# RL7005_IP_SVD register map
Vendor: Realtek
Registers are 32-bit, read-write, reset 0x0 unless marked. A register's access mark holds for its fields unless they carry their own. Offsets are from the block's base; [hi:lo] are bit positions; lines under a group give offsets from that group; {n}, {i} and the like mark numbered series.

## SYSTEM_MEM_CTRL
Base 0x4080A600
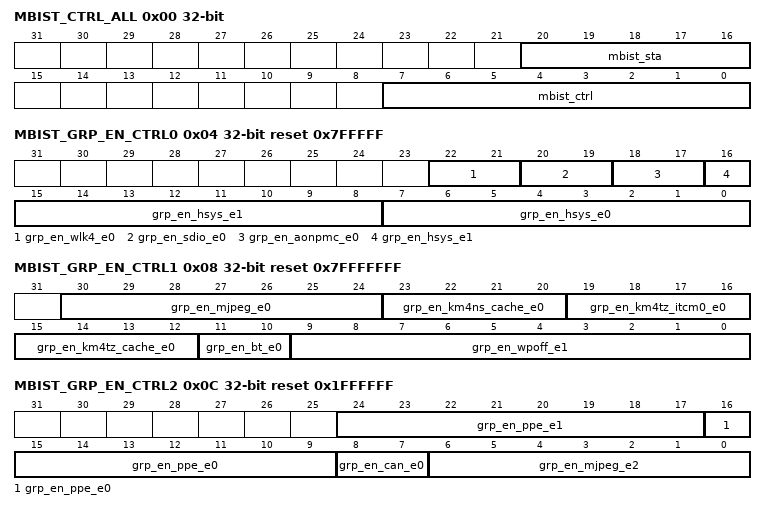
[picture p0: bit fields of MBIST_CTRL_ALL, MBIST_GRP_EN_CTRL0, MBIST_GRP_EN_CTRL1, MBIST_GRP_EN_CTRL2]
0x00 MBIST_CTRL_ALL access per field — MEMx MBIST control and status register
  [20:16] mbist_sta ro — Total mbist status [16] MBIST DRF_START_PAUSE [17] MBIST NRML_DONE_ALL [18] MBIST NRML_FAIL_ALL [19] MBIST DRF_DONE_ALL [20] MBIST DRF_FAIL_ALL
  [7:0] mbist_ctrl rw — Total mbist control [0] MBIST_CLK_EN_ALL BIS_CLK enable of all system memory groups. [1] MBIST_RSTB_ALL Reset controll mbist circuit of all system memory groups. [3:2]MBIST_MSEL_ALL mbist method selection of all memory groups: 2'b01: enable normal mode mbist 2'b10: enable DRF mode mbist 2'b11: enable normal&DRF mode mbist [4]MBIST_RESUME [5]MBIST_RESUME_PS [6]MBIST_DYN_READ_EN If MBIST_MSEL_ALL[1]=1 & MBIST_DYN_READ_EN=1, run VDDR mode mbist. 7]MBIST_PHYCLK_STOP
0x04 MBIST_GRP_EN_CTRL0 reset 0x7FFFFF — Used to on-off mbist of memory block in a group.
  [22:21] grp_en_wlk4_e0, [20:19] grp_en_sdio_e0, [18:17] grp_en_aonpmc_e0, [16:8] grp_en_hsys_e1, [7:0] grp_en_hsys_e0
0x08 MBIST_GRP_EN_CTRL1 reset 0x7FFFFFFF — Used to on-off mbist of memory block in a group.
  [30:24] grp_en_mjpeg_e0, [23:20] grp_en_km4ns_cache_e0, [19:16] grp_en_km4tz_itcm0_e0, [15:12] grp_en_km4tz_cache_e0, [11:10] grp_en_bt_e0, [9:0] grp_en_wpoff_e1
0x0C MBIST_GRP_EN_CTRL2 reset 0x1FFFFFF — Used to on-off mbist of memory block in a group.
  [24:17] grp_en_ppe_e1, [16:9] grp_en_ppe_e0, [8:7] grp_en_can_e0, [6:0] grp_en_mjpeg_e2
0x10 MBIST_GRP_EN_BT_VIR_E00 reset 0xFFFFF
  [19:0] bt_vir_e0_bist_en_19_0
0x14 MBIST_DONE_STA0 ro
  [31:0] mbist_done_31_0
0x18 MBIST_START_PULSE0 ro
  [31:0] mbist_start_pause_31_0
{0x1C+4i} MBIST_NORM_FAIL{i} ro (i=0..2)
  [31:0] mbist_norm_fail_{32i+31}_{32i}
0x28 MBIST_NORM_FAIL3 ro
  [3:0] mbist_norm_fail_99_96
{0x2C+4i} MBIST_DRF_FAIL{i} ro (i=0..2)
  [31:0] mbist_drf_fail_{32i+31}_{32i}
0x38 MBIST_DRF_FAIL3 ro
  [3:0] mbist_drf_fail_99_96
0x3C BT_VIR_E0_BIST_DONE0 ro
  [19:0] bt_vir_e0_mbist_done_19_0
0x40 BT_VIR_E0_BIST_FAIL0 ro
  [19:0] bt_vir_e0_mbist_fail_19_0
0x44 BT_VIR_E0_BIST_DRF_PAUSE0 ro
  [19:0] bt_vir_e0_mbist_drf_pause_19_0
0x48 BT_VIR_E0_BIST_RPT ro
  [31:0] bt_vir_e0_bist_rpt_dout
0x4C BT_VIR_E0_RPT_SEL
  [3:0] bt_vir_e0_rpt_sel — Select which rom's misr_dataout or bist_status of each memory can be read from bt_vir_e0_bist_rpt
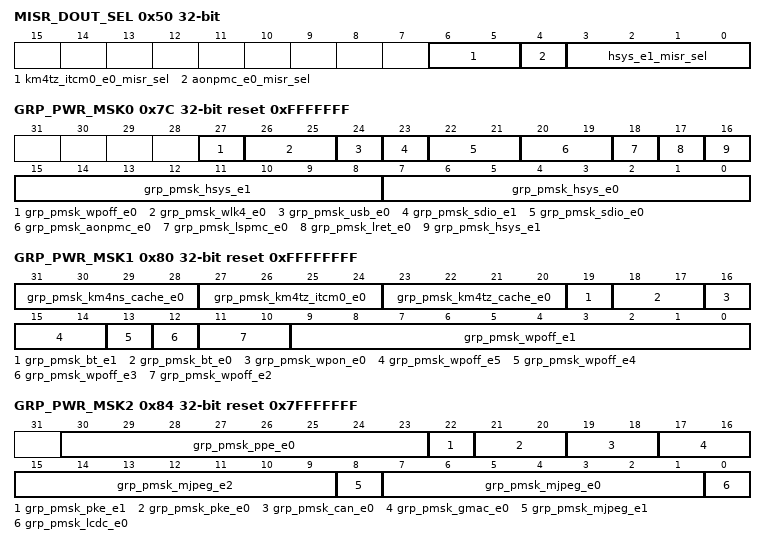
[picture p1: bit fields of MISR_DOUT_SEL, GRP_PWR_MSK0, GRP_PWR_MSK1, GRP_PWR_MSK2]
0x50 MISR_DOUT_SEL
  [6:5] km4tz_itcm0_e0_misr_sel, [4] aonpmc_e0_misr_sel, [3:0] hsys_e1_misr_sel
0x54 HSYS_E1_ROM_MISR0 ro
  [31:0] hsys_e1_misr_dout_31_0
0x58 HSYS_E1_ROM_MISR1 ro
  [31:0] hsys_e1_misr_dout_63_32
0x5C LSPMC_E0_ROM_MISR1 ro
  [31:0] lspmc_e0_misr_dout_31_0
0x60 LSPMC_E0_ROM_MISR2 ro
  [3:0] lspmc_e0_misr_dout_35_32
0x64 AONPMC_E0_ROM_MISR2 ro
  [31:0] aonpmc_e0_misr_dout_31_0
0x68 AONPMC_E0_ROM_MISR3 ro
  [3:0] aonpmc_e0_misr_dout_35_32
0x6C KM4TZ_ITCM0_E0_ROM_MISR3 ro
  [31:0] km4tz_itcm0_e0_misr_dout_31_0
0x70 KM4TZ_ITCM0_E0_ROM_MISR4 ro
  [31:0] km4tz_itcm0_e0_misr_dout_63_32
0x74 PKE_E1_ROM_MISR4 ro
  [31:0] pke_e1_misr_dout_31_0
0x78 PKE_E1_ROM_MISR5 ro
  [31:0] pke_e1_misr_dout_63_32
0x7C GRP_PWR_MSK0 reset 0xFFFFFFF
  [27] grp_pmsk_wpoff_e0, [26:25] grp_pmsk_wlk4_e0, [24] grp_pmsk_usb_e0, [23] grp_pmsk_sdio_e1, [22:21] grp_pmsk_sdio_e0, [20:19] grp_pmsk_aonpmc_e0, [18] grp_pmsk_lspmc_e0, [17] grp_pmsk_lret_e0, [16:8] grp_pmsk_hsys_e1, [7:0] grp_pmsk_hsys_e0
0x80 GRP_PWR_MSK1 reset 0xFFFFFFFF
  [31:28] grp_pmsk_km4ns_cache_e0, [27:24] grp_pmsk_km4tz_itcm0_e0, [23:20] grp_pmsk_km4tz_cache_e0, [19] grp_pmsk_bt_e1, [18:17] grp_pmsk_bt_e0, [16] grp_pmsk_wpon_e0, [15:14] grp_pmsk_wpoff_e5, [13] grp_pmsk_wpoff_e4, [12] grp_pmsk_wpoff_e3, [11:10] grp_pmsk_wpoff_e2, [9:0] grp_pmsk_wpoff_e1
0x84 GRP_PWR_MSK2 reset 0x7FFFFFFF
  [30:23] grp_pmsk_ppe_e0, [22] grp_pmsk_pke_e1, [21:20] grp_pmsk_pke_e0, [19:18] grp_pmsk_can_e0, [17:16] grp_pmsk_gmac_e0, [15:9] grp_pmsk_mjpeg_e2, [8] grp_pmsk_mjpeg_e1, [7:1] grp_pmsk_mjpeg_e0, [0] grp_pmsk_lcdc_e0
0x88 GRP_PWR_MSK3 reset 0xFF
  [7:0] grp_pmsk_ppe_e1
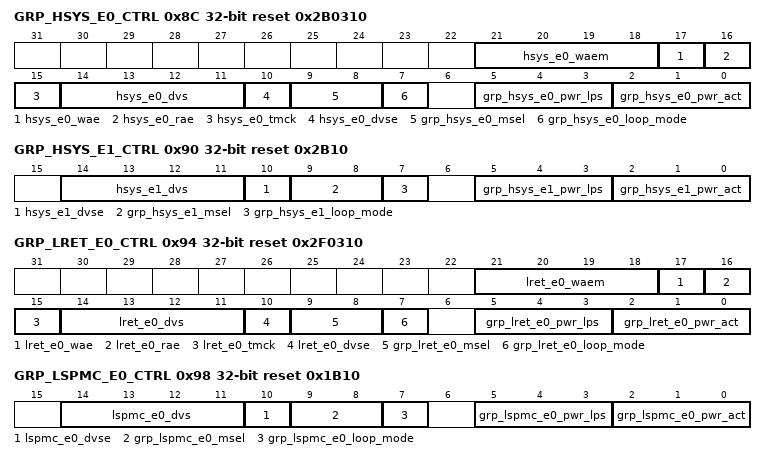
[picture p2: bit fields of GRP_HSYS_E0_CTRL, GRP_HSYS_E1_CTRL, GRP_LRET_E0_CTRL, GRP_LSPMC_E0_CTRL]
0x8C GRP_HSYS_E0_CTRL reset 0x2B0310
  [21:18] hsys_e0_waem — WAEM
  [17] hsys_e0_wae — WAE
  [16] hsys_e0_rae — RAE
  [15] hsys_e0_tmck — TMCK
  [14:11] hsys_e0_dvs — DVS
  [10] hsys_e0_dvse — DVSE
  [9:8] grp_hsys_e0_msel — *01 - This memory group can do normal mbist; *10 - This memory group can do DRF mbist; *11 - This memory group can do normal & DRF mbist
  [7] grp_hsys_e0_loop_mode — *0 - Assist loop mode; *1 - Don't assist loop mode
  [5:3] grp_hsys_e0_pwr_lps — Reserved for grp_@_pwr_lps for memory groups power controlled by SYSPMC. Setted before chip goes to SLEEP.Used to controll power mode of this memory group when chip is in SLEEP. For FTC_ULP mem, pwr_lps[2:0] map to {SLP,RET,NAP}; For SNPS mem, pwr_lps[2:0] map to {SD,DS,LS}. *000 - active *001 - light sleep *010 - deep sleep *100 - shut down
  [2:0] grp_hsys_e0_pwr_act — Used to controll power mode of this memory group when chip is ACTIVE. For FTC_ULP mem, pwr_act[2:0] map to {SLP,RET,NAP}; For SNPS mem, pwr_act[2:0] map to {SD,DS,LS}. *000 - active *001 - light sleep *010 - deep sleep *100 - shut down
0x90 GRP_HSYS_E1_CTRL reset 0x2B10
  [14:11] hsys_e1_dvs — DVS
  [10] hsys_e1_dvse — DVSE
  [9:8] grp_hsys_e1_msel — *01 - This memory group can do normal mbist; *10 - This memory group can do DRF mbist; *11 - This memory group can do normal & DRF mbist
  [7] grp_hsys_e1_loop_mode — *0 - Assist loop mode; *1 - Don't assist loop mode
  [5:3] grp_hsys_e1_pwr_lps — Reserved for grp_@_pwr_lps for memory groups power controlled by SYSPMC. Setted before chip goes to SLEEP.Used to controll power mode of this memory group when chip is in SLEEP. For FTC_ULP mem, pwr_lps[2:0] map to {SLP,RET,NAP}; For SNPS mem, pwr_lps[2:0] map to {SD,DS,LS}. *000 - active *001 - light sleep *010 - deep sleep *100 - shut down
  [2:0] grp_hsys_e1_pwr_act — Used to controll power mode of this memory group when chip is ACTIVE. For FTC_ULP mem, pwr_act[2:0] map to {SLP,RET,NAP}; For SNPS mem, pwr_act[2:0] map to {SD,DS,LS}. *000 - active *001 - light sleep *010 - deep sleep *100 - shut down
0x94 GRP_LRET_E0_CTRL reset 0x2F0310
  [21:18] lret_e0_waem — WAEM
  [17] lret_e0_wae — WAE
  [16] lret_e0_rae — RAE
  [15] lret_e0_tmck — TMCK
  [14:11] lret_e0_dvs — DVS
  [10] lret_e0_dvse — DVSE
  [9:8] grp_lret_e0_msel — *01 - This memory group can do normal mbist; *10 - This memory group can do DRF mbist; *11 - This memory group can do normal & DRF mbist
  [7] grp_lret_e0_loop_mode — *0 - Assist loop mode; *1 - Don't assist loop mode
  [5:3] grp_lret_e0_pwr_lps — Reserved for grp_@_pwr_lps for memory groups power controlled by SYSPMC. Setted before chip goes to SLEEP.Used to controll power mode of this memory group when chip is in SLEEP. For FTC_ULP mem, pwr_lps[2:0] map to {SLP,RET,NAP}; For SNPS mem, pwr_lps[2:0] map to {SD,DS,LS}. *000 - active *001 - light sleep *010 - deep sleep *100 - shut down
  [2:0] grp_lret_e0_pwr_act — Used to controll power mode of this memory group when chip is ACTIVE. For FTC_ULP mem, pwr_act[2:0] map to {SLP,RET,NAP}; For SNPS mem, pwr_act[2:0] map to {SD,DS,LS}. *000 - active *001 - light sleep *010 - deep sleep *100 - shut down
0x98 GRP_LSPMC_E0_CTRL reset 0x1B10
  [14:11] lspmc_e0_dvs — DVS
  [10] lspmc_e0_dvse — DVSE
  [9:8] grp_lspmc_e0_msel — *01 - This memory group can do normal mbist; *10 - This memory group can do DRF mbist; *11 - This memory group can do normal & DRF mbist
  [7] grp_lspmc_e0_loop_mode — *0 - Assist loop mode; *1 - Don't assist loop mode
  [5:3] grp_lspmc_e0_pwr_lps — Reserved for grp_@_pwr_lps for memory groups power controlled by SYSPMC. Setted before chip goes to SLEEP.Used to controll power mode of this memory group when chip is in SLEEP. For FTC_ULP mem, pwr_lps[2:0] map to {SLP,RET,NAP}; For SNPS mem, pwr_lps[2:0] map to {SD,DS,LS}. *000 - active *001 - light sleep *010 - deep sleep *100 - shut down
  [2:0] grp_lspmc_e0_pwr_act — Used to controll power mode of this memory group when chip is ACTIVE. For FTC_ULP mem, pwr_act[2:0] map to {SLP,RET,NAP}; For SNPS mem, pwr_act[2:0] map to {SD,DS,LS}. *000 - active *001 - light sleep *010 - deep sleep *100 - shut down
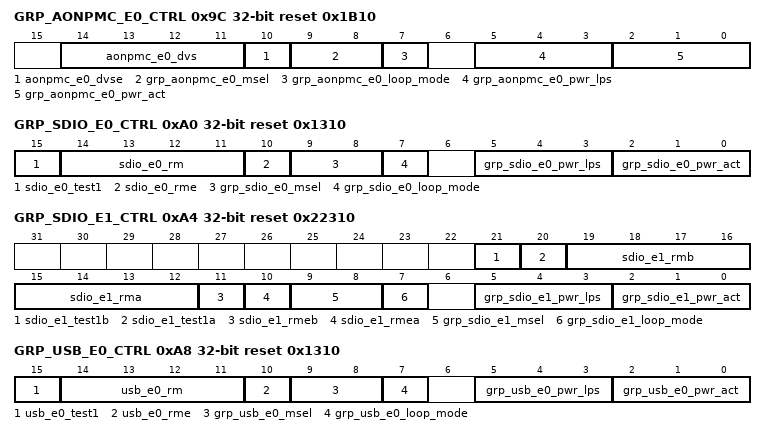
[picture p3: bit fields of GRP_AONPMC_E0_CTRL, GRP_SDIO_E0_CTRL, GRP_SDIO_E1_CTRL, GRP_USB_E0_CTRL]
0x9C GRP_AONPMC_E0_CTRL reset 0x1B10
  [14:11] aonpmc_e0_dvs — DVS
  [10] aonpmc_e0_dvse — DVSE
  [9:8] grp_aonpmc_e0_msel — *01 - This memory group can do normal mbist; *10 - This memory group can do DRF mbist; *11 - This memory group can do normal & DRF mbist
  [7] grp_aonpmc_e0_loop_mode — *0 - Assist loop mode; *1 - Don't assist loop mode
  [5:3] grp_aonpmc_e0_pwr_lps — Reserved for grp_@_pwr_lps for memory groups power controlled by SYSPMC. Setted before chip goes to SLEEP.Used to controll power mode of this memory group when chip is in SLEEP. For FTC_ULP mem, pwr_lps[2:0] map to {SLP,RET,NAP}; For SNPS mem, pwr_lps[2:0] map to {SD,DS,LS}. *000 - active *001 - light sleep *010 - deep sleep *100 - shut down
  [2:0] grp_aonpmc_e0_pwr_act — Used to controll power mode of this memory group when chip is ACTIVE. For FTC_ULP mem, pwr_act[2:0] map to {SLP,RET,NAP}; For SNPS mem, pwr_act[2:0] map to {SD,DS,LS}. *000 - active *001 - light sleep *010 - deep sleep *100 - shut down
0xA0 GRP_SDIO_E0_CTRL reset 0x1310
  [15] sdio_e0_test1 — TEST1
  [14:11] sdio_e0_rm — RM
  [10] sdio_e0_rme — RME
  [9:8] grp_sdio_e0_msel — *01 - This memory group can do normal mbist; *10 - This memory group can do DRF mbist; *11 - This memory group can do normal & DRF mbist
  [7] grp_sdio_e0_loop_mode — *0 - Assist loop mode; *1 - Don't assist loop mode
  [5:3] grp_sdio_e0_pwr_lps — Reserved for grp_@_pwr_lps for memory groups power controlled by SYSPMC. Setted before chip goes to SLEEP.Used to controll power mode of this memory group when chip is in SLEEP. For FTC_ULP mem, pwr_lps[2:0] map to {SLP,RET,NAP}; For SNPS mem, pwr_lps[2:0] map to {SD,DS,LS}. *000 - active *001 - light sleep *010 - deep sleep *100 - shut down
  [2:0] grp_sdio_e0_pwr_act — Used to controll power mode of this memory group when chip is ACTIVE. For FTC_ULP mem, pwr_act[2:0] map to {SLP,RET,NAP}; For SNPS mem, pwr_act[2:0] map to {SD,DS,LS}. *000 - active *001 - light sleep *010 - deep sleep *100 - shut down
0xA4 GRP_SDIO_E1_CTRL reset 0x22310
  [21] sdio_e1_test1b — TEST1B
  [20] sdio_e1_test1a — TEST1A
  [19:16] sdio_e1_rmb — RMB
  [15:12] sdio_e1_rma — RMA
  [11] sdio_e1_rmeb — RMEB
  [10] sdio_e1_rmea — RMEA
  [9:8] grp_sdio_e1_msel — *01 - This memory group can do normal mbist; *10 - This memory group can do DRF mbist; *11 - This memory group can do normal & DRF mbist
  [7] grp_sdio_e1_loop_mode — *0 - Assist loop mode; *1 - Don't assist loop mode
  [5:3] grp_sdio_e1_pwr_lps — Reserved for grp_@_pwr_lps for memory groups power controlled by SYSPMC. Setted before chip goes to SLEEP.Used to controll power mode of this memory group when chip is in SLEEP. For FTC_ULP mem, pwr_lps[2:0] map to {SLP,RET,NAP}; For SNPS mem, pwr_lps[2:0] map to {SD,DS,LS}. *000 - active *001 - light sleep *010 - deep sleep *100 - shut down
  [2:0] grp_sdio_e1_pwr_act — Used to controll power mode of this memory group when chip is ACTIVE. For FTC_ULP mem, pwr_act[2:0] map to {SLP,RET,NAP}; For SNPS mem, pwr_act[2:0] map to {SD,DS,LS}. *000 - active *001 - light sleep *010 - deep sleep *100 - shut down
0xA8 GRP_USB_E0_CTRL reset 0x1310
  [15] usb_e0_test1 — TEST1
  [14:11] usb_e0_rm — RM
  [10] usb_e0_rme — RME
  [9:8] grp_usb_e0_msel — *01 - This memory group can do normal mbist; *10 - This memory group can do DRF mbist; *11 - This memory group can do normal & DRF mbist
  [7] grp_usb_e0_loop_mode — *0 - Assist loop mode; *1 - Don't assist loop mode
  [5:3] grp_usb_e0_pwr_lps — Reserved for grp_@_pwr_lps for memory groups power controlled by SYSPMC. Setted before chip goes to SLEEP.Used to controll power mode of this memory group when chip is in SLEEP. For FTC_ULP mem, pwr_lps[2:0] map to {SLP,RET,NAP}; For SNPS mem, pwr_lps[2:0] map to {SD,DS,LS}. *000 - active *001 - light sleep *010 - deep sleep *100 - shut down
  [2:0] grp_usb_e0_pwr_act — Used to controll power mode of this memory group when chip is ACTIVE. For FTC_ULP mem, pwr_act[2:0] map to {SLP,RET,NAP}; For SNPS mem, pwr_act[2:0] map to {SD,DS,LS}. *000 - active *001 - light sleep *010 - deep sleep *100 - shut down
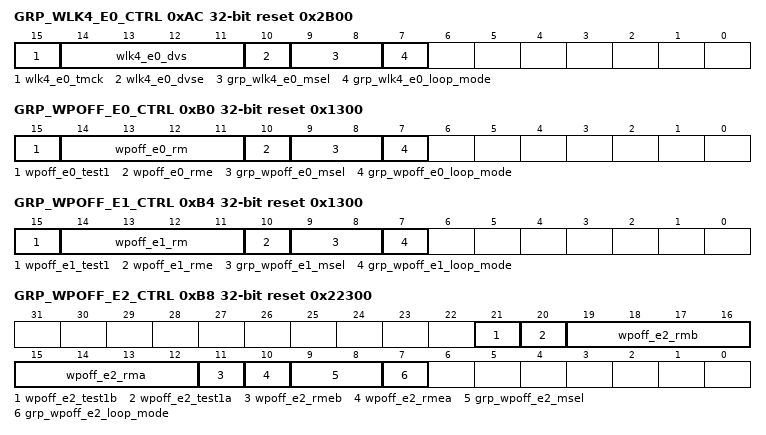
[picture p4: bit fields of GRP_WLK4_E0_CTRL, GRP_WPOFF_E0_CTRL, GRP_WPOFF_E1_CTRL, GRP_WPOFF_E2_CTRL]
0xAC GRP_WLK4_E0_CTRL reset 0x2B00
  [15] wlk4_e0_tmck — TMCK
  [14:11] wlk4_e0_dvs — DVS
  [10] wlk4_e0_dvse — DVSE
  [9:8] grp_wlk4_e0_msel — *01 - This memory group can do normal mbist; *10 - This memory group can do DRF mbist; *11 - This memory group can do normal & DRF mbist
  [7] grp_wlk4_e0_loop_mode — *0 - Assist loop mode; *1 - Don't assist loop mode
0xB0 GRP_WPOFF_E0_CTRL reset 0x1300
  [15] wpoff_e0_test1 — TEST1
  [14:11] wpoff_e0_rm — RM
  [10] wpoff_e0_rme — RME
  [9:8] grp_wpoff_e0_msel — *01 - This memory group can do normal mbist; *10 - This memory group can do DRF mbist; *11 - This memory group can do normal & DRF mbist
  [7] grp_wpoff_e0_loop_mode — *0 - Assist loop mode; *1 - Don't assist loop mode
0xB4 GRP_WPOFF_E1_CTRL reset 0x1300
  [15] wpoff_e1_test1 — TEST1
  [14:11] wpoff_e1_rm — RM
  [10] wpoff_e1_rme — RME
  [9:8] grp_wpoff_e1_msel — *01 - This memory group can do normal mbist; *10 - This memory group can do DRF mbist; *11 - This memory group can do normal & DRF mbist
  [7] grp_wpoff_e1_loop_mode — *0 - Assist loop mode; *1 - Don't assist loop mode
0xB8 GRP_WPOFF_E2_CTRL reset 0x22300
  [21] wpoff_e2_test1b — TEST1B
  [20] wpoff_e2_test1a — TEST1A
  [19:16] wpoff_e2_rmb — RMB
  [15:12] wpoff_e2_rma — RMA
  [11] wpoff_e2_rmeb — RMEB
  [10] wpoff_e2_rmea — RMEA
  [9:8] grp_wpoff_e2_msel — *01 - This memory group can do normal mbist; *10 - This memory group can do DRF mbist; *11 - This memory group can do normal & DRF mbist
  [7] grp_wpoff_e2_loop_mode — *0 - Assist loop mode; *1 - Don't assist loop mode
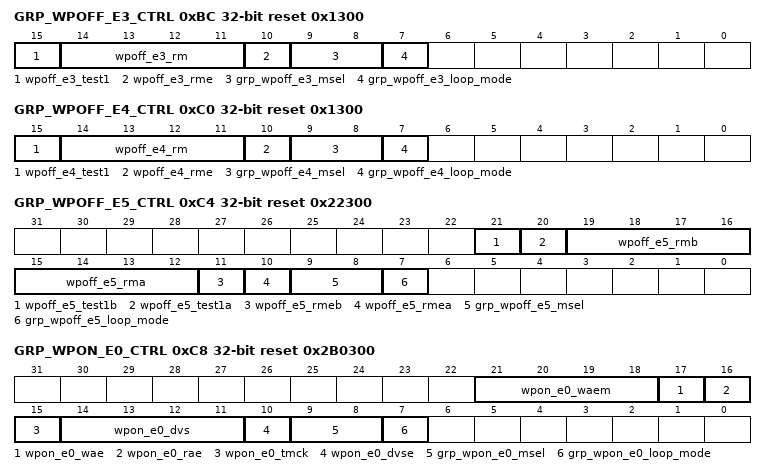
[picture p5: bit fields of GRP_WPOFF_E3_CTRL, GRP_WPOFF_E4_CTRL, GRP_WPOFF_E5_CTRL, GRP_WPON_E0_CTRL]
0xBC GRP_WPOFF_E3_CTRL reset 0x1300
  [15] wpoff_e3_test1 — TEST1
  [14:11] wpoff_e3_rm — RM
  [10] wpoff_e3_rme — RME
  [9:8] grp_wpoff_e3_msel — *01 - This memory group can do normal mbist; *10 - This memory group can do DRF mbist; *11 - This memory group can do normal & DRF mbist
  [7] grp_wpoff_e3_loop_mode — *0 - Assist loop mode; *1 - Don't assist loop mode
0xC0 GRP_WPOFF_E4_CTRL reset 0x1300
  [15] wpoff_e4_test1 — TEST1
  [14:11] wpoff_e4_rm — RM
  [10] wpoff_e4_rme — RME
  [9:8] grp_wpoff_e4_msel — *01 - This memory group can do normal mbist; *10 - This memory group can do DRF mbist; *11 - This memory group can do normal & DRF mbist
  [7] grp_wpoff_e4_loop_mode — *0 - Assist loop mode; *1 - Don't assist loop mode
0xC4 GRP_WPOFF_E5_CTRL reset 0x22300
  [21] wpoff_e5_test1b — TEST1B
  [20] wpoff_e5_test1a — TEST1A
  [19:16] wpoff_e5_rmb — RMB
  [15:12] wpoff_e5_rma — RMA
  [11] wpoff_e5_rmeb — RMEB
  [10] wpoff_e5_rmea — RMEA
  [9:8] grp_wpoff_e5_msel — *01 - This memory group can do normal mbist; *10 - This memory group can do DRF mbist; *11 - This memory group can do normal & DRF mbist
  [7] grp_wpoff_e5_loop_mode — *0 - Assist loop mode; *1 - Don't assist loop mode
0xC8 GRP_WPON_E0_CTRL reset 0x2B0300
  [21:18] wpon_e0_waem — WAEM
  [17] wpon_e0_wae — WAE
  [16] wpon_e0_rae — RAE
  [15] wpon_e0_tmck — TMCK
  [14:11] wpon_e0_dvs — DVS
  [10] wpon_e0_dvse — DVSE
  [9:8] grp_wpon_e0_msel — *01 - This memory group can do normal mbist; *10 - This memory group can do DRF mbist; *11 - This memory group can do normal & DRF mbist
  [7] grp_wpon_e0_loop_mode — *0 - Assist loop mode; *1 - Don't assist loop mode
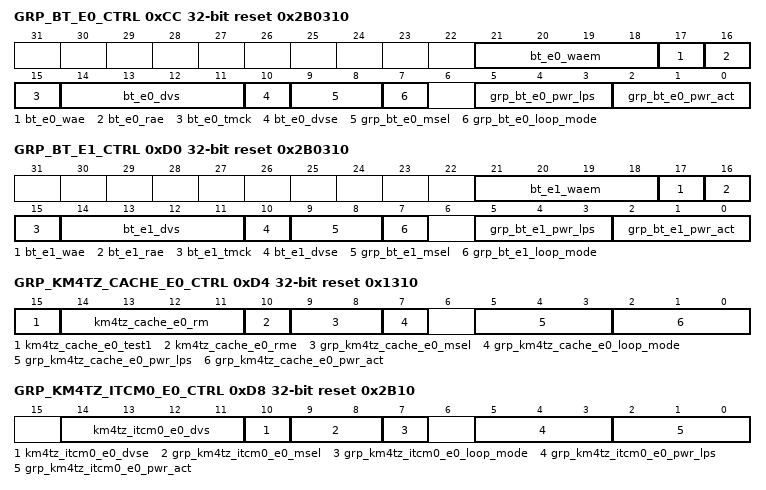
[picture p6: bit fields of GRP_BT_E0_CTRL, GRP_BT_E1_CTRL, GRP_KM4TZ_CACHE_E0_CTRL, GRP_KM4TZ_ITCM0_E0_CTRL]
0xCC GRP_BT_E0_CTRL reset 0x2B0310
  [21:18] bt_e0_waem — WAEM
  [17] bt_e0_wae — WAE
  [16] bt_e0_rae — RAE
  [15] bt_e0_tmck — TMCK
  [14:11] bt_e0_dvs — DVS
  [10] bt_e0_dvse — DVSE
  [9:8] grp_bt_e0_msel — *01 - This memory group can do normal mbist; *10 - This memory group can do DRF mbist; *11 - This memory group can do normal & DRF mbist
  [7] grp_bt_e0_loop_mode — *0 - Assist loop mode; *1 - Don't assist loop mode
  [5:3] grp_bt_e0_pwr_lps — Reserved for grp_@_pwr_lps for memory groups power controlled by SYSPMC. Setted before chip goes to SLEEP.Used to controll power mode of this memory group when chip is in SLEEP. For FTC_ULP mem, pwr_lps[2:0] map to {SLP,RET,NAP}; For SNPS mem, pwr_lps[2:0] map to {SD,DS,LS}. *000 - active *001 - light sleep *010 - deep sleep *100 - shut down
  [2:0] grp_bt_e0_pwr_act — Used to controll power mode of this memory group when chip is ACTIVE. For FTC_ULP mem, pwr_act[2:0] map to {SLP,RET,NAP}; For SNPS mem, pwr_act[2:0] map to {SD,DS,LS}. *000 - active *001 - light sleep *010 - deep sleep *100 - shut down
0xD0 GRP_BT_E1_CTRL reset 0x2B0310
  [21:18] bt_e1_waem — WAEM
  [17] bt_e1_wae — WAE
  [16] bt_e1_rae — RAE
  [15] bt_e1_tmck — TMCK
  [14:11] bt_e1_dvs — DVS
  [10] bt_e1_dvse — DVSE
  [9:8] grp_bt_e1_msel — *01 - This memory group can do normal mbist; *10 - This memory group can do DRF mbist; *11 - This memory group can do normal & DRF mbist
  [7] grp_bt_e1_loop_mode — *0 - Assist loop mode; *1 - Don't assist loop mode
  [5:3] grp_bt_e1_pwr_lps — Reserved for grp_@_pwr_lps for memory groups power controlled by SYSPMC. Setted before chip goes to SLEEP.Used to controll power mode of this memory group when chip is in SLEEP. For FTC_ULP mem, pwr_lps[2:0] map to {SLP,RET,NAP}; For SNPS mem, pwr_lps[2:0] map to {SD,DS,LS}. *000 - active *001 - light sleep *010 - deep sleep *100 - shut down
  [2:0] grp_bt_e1_pwr_act — Used to controll power mode of this memory group when chip is ACTIVE. For FTC_ULP mem, pwr_act[2:0] map to {SLP,RET,NAP}; For SNPS mem, pwr_act[2:0] map to {SD,DS,LS}. *000 - active *001 - light sleep *010 - deep sleep *100 - shut down
0xD4 GRP_KM4TZ_CACHE_E0_CTRL reset 0x1310
  [15] km4tz_cache_e0_test1 — TEST1
  [14:11] km4tz_cache_e0_rm — RM
  [10] km4tz_cache_e0_rme — RME
  [9:8] grp_km4tz_cache_e0_msel — *01 - This memory group can do normal mbist; *10 - This memory group can do DRF mbist; *11 - This memory group can do normal & DRF mbist
  [7] grp_km4tz_cache_e0_loop_mode — *0 - Assist loop mode; *1 - Don't assist loop mode
  [5:3] grp_km4tz_cache_e0_pwr_lps — Reserved for grp_@_pwr_lps for memory groups power controlled by SYSPMC. Setted before chip goes to SLEEP.Used to controll power mode of this memory group when chip is in SLEEP. For FTC_ULP mem, pwr_lps[2:0] map to {SLP,RET,NAP}; For SNPS mem, pwr_lps[2:0] map to {SD,DS,LS}. *000 - active *001 - light sleep *010 - deep sleep *100 - shut down
  [2:0] grp_km4tz_cache_e0_pwr_act — Used to controll power mode of this memory group when chip is ACTIVE. For FTC_ULP mem, pwr_act[2:0] map to {SLP,RET,NAP}; For SNPS mem, pwr_act[2:0] map to {SD,DS,LS}. *000 - active *001 - light sleep *010 - deep sleep *100 - shut down
0xD8 GRP_KM4TZ_ITCM0_E0_CTRL reset 0x2B10
  [14:11] km4tz_itcm0_e0_dvs — DVS
  [10] km4tz_itcm0_e0_dvse — DVSE
  [9:8] grp_km4tz_itcm0_e0_msel — *01 - This memory group can do normal mbist; *10 - This memory group can do DRF mbist; *11 - This memory group can do normal & DRF mbist
  [7] grp_km4tz_itcm0_e0_loop_mode — *0 - Assist loop mode; *1 - Don't assist loop mode
  [5:3] grp_km4tz_itcm0_e0_pwr_lps — Reserved for grp_@_pwr_lps for memory groups power controlled by SYSPMC. Setted before chip goes to SLEEP.Used to controll power mode of this memory group when chip is in SLEEP. For FTC_ULP mem, pwr_lps[2:0] map to {SLP,RET,NAP}; For SNPS mem, pwr_lps[2:0] map to {SD,DS,LS}. *000 - active *001 - light sleep *010 - deep sleep *100 - shut down
  [2:0] grp_km4tz_itcm0_e0_pwr_act — Used to controll power mode of this memory group when chip is ACTIVE. For FTC_ULP mem, pwr_act[2:0] map to {SLP,RET,NAP}; For SNPS mem, pwr_act[2:0] map to {SD,DS,LS}. *000 - active *001 - light sleep *010 - deep sleep *100 - shut down
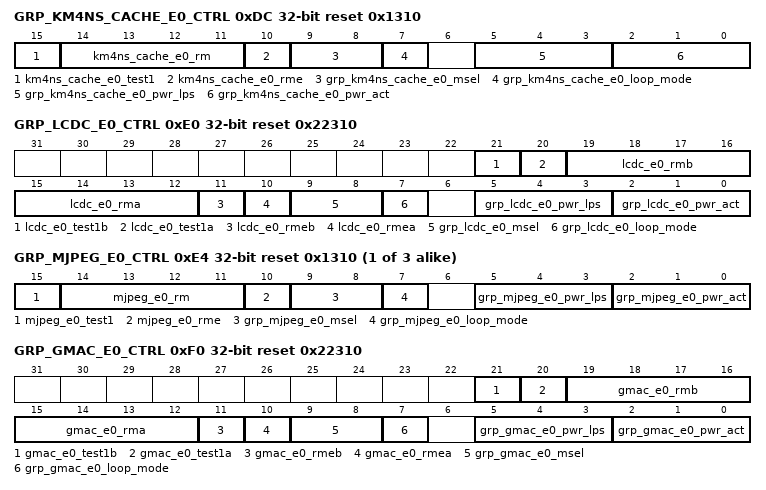
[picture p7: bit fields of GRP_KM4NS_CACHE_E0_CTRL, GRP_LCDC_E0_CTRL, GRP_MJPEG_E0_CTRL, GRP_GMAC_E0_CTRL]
0xDC GRP_KM4NS_CACHE_E0_CTRL reset 0x1310
  [15] km4ns_cache_e0_test1 — TEST1
  [14:11] km4ns_cache_e0_rm — RM
  [10] km4ns_cache_e0_rme — RME
  [9:8] grp_km4ns_cache_e0_msel — *01 - This memory group can do normal mbist; *10 - This memory group can do DRF mbist; *11 - This memory group can do normal & DRF mbist
  [7] grp_km4ns_cache_e0_loop_mode — *0 - Assist loop mode; *1 - Don't assist loop mode
  [5:3] grp_km4ns_cache_e0_pwr_lps — Reserved for grp_@_pwr_lps for memory groups power controlled by SYSPMC. Setted before chip goes to SLEEP.Used to controll power mode of this memory group when chip is in SLEEP. For FTC_ULP mem, pwr_lps[2:0] map to {SLP,RET,NAP}; For SNPS mem, pwr_lps[2:0] map to {SD,DS,LS}. *000 - active *001 - light sleep *010 - deep sleep *100 - shut down
  [2:0] grp_km4ns_cache_e0_pwr_act — Used to controll power mode of this memory group when chip is ACTIVE. For FTC_ULP mem, pwr_act[2:0] map to {SLP,RET,NAP}; For SNPS mem, pwr_act[2:0] map to {SD,DS,LS}. *000 - active *001 - light sleep *010 - deep sleep *100 - shut down
0xE0 GRP_LCDC_E0_CTRL reset 0x22310
  [21] lcdc_e0_test1b — TEST1B
  [20] lcdc_e0_test1a — TEST1A
  [19:16] lcdc_e0_rmb — RMB
  [15:12] lcdc_e0_rma — RMA
  [11] lcdc_e0_rmeb — RMEB
  [10] lcdc_e0_rmea — RMEA
  [9:8] grp_lcdc_e0_msel — *01 - This memory group can do normal mbist; *10 - This memory group can do DRF mbist; *11 - This memory group can do normal & DRF mbist
  [7] grp_lcdc_e0_loop_mode — *0 - Assist loop mode; *1 - Don't assist loop mode
  [5:3] grp_lcdc_e0_pwr_lps — Reserved for grp_@_pwr_lps for memory groups power controlled by SYSPMC. Setted before chip goes to SLEEP.Used to controll power mode of this memory group when chip is in SLEEP. For FTC_ULP mem, pwr_lps[2:0] map to {SLP,RET,NAP}; For SNPS mem, pwr_lps[2:0] map to {SD,DS,LS}. *000 - active *001 - light sleep *010 - deep sleep *100 - shut down
  [2:0] grp_lcdc_e0_pwr_act — Used to controll power mode of this memory group when chip is ACTIVE. For FTC_ULP mem, pwr_act[2:0] map to {SLP,RET,NAP}; For SNPS mem, pwr_act[2:0] map to {SD,DS,LS}. *000 - active *001 - light sleep *010 - deep sleep *100 - shut down
{0xE4+4i} GRP_MJPEG_E{i}_CTRL reset 0x1310 (i=0..2)
  [15] mjpeg_e{i}_test1 — TEST1
  [14:11] mjpeg_e{i}_rm — RM
  [10] mjpeg_e{i}_rme — RME
  [9:8] grp_mjpeg_e{i}_msel — *01 - This memory group can do normal mbist; *10 - This memory group can do DRF mbist; *11 - This memory group can do normal & DRF mbist
  [7] grp_mjpeg_e{i}_loop_mode — *0 - Assist loop mode; *1 - Don't assist loop mode
  [5:3] grp_mjpeg_e{i}_pwr_lps — Reserved for grp_@_pwr_lps for memory groups power controlled by SYSPMC. Setted before chip goes to SLEEP.Used to controll power mode of this memory group when chip is in SLEEP. For FTC_ULP mem, pwr_lps[2:0] map to {SLP,RET,NAP}; For SNPS mem, pwr_lps[2:0] map to {SD,DS,LS}. *000 - active *001 - light sleep *010 - deep sleep *100 - shut down
  [2:0] grp_mjpeg_e{i}_pwr_act — Used to controll power mode of this memory group when chip is ACTIVE. For FTC_ULP mem, pwr_act[2:0] map to {SLP,RET,NAP}; For SNPS mem, pwr_act[2:0] map to {SD,DS,LS}. *000 - active *001 - light sleep *010 - deep sleep *100 - shut down
0xF0 GRP_GMAC_E0_CTRL reset 0x22310
  [21] gmac_e0_test1b — TEST1B
  [20] gmac_e0_test1a — TEST1A
  [19:16] gmac_e0_rmb — RMB
  [15:12] gmac_e0_rma — RMA
  [11] gmac_e0_rmeb — RMEB
  [10] gmac_e0_rmea — RMEA
  [9:8] grp_gmac_e0_msel — *01 - This memory group can do normal mbist; *10 - This memory group can do DRF mbist; *11 - This memory group can do normal & DRF mbist
  [7] grp_gmac_e0_loop_mode — *0 - Assist loop mode; *1 - Don't assist loop mode
  [5:3] grp_gmac_e0_pwr_lps — Reserved for grp_@_pwr_lps for memory groups power controlled by SYSPMC. Setted before chip goes to SLEEP.Used to controll power mode of this memory group when chip is in SLEEP. For FTC_ULP mem, pwr_lps[2:0] map to {SLP,RET,NAP}; For SNPS mem, pwr_lps[2:0] map to {SD,DS,LS}. *000 - active *001 - light sleep *010 - deep sleep *100 - shut down
  [2:0] grp_gmac_e0_pwr_act — Used to controll power mode of this memory group when chip is ACTIVE. For FTC_ULP mem, pwr_act[2:0] map to {SLP,RET,NAP}; For SNPS mem, pwr_act[2:0] map to {SD,DS,LS}. *000 - active *001 - light sleep *010 - deep sleep *100 - shut down
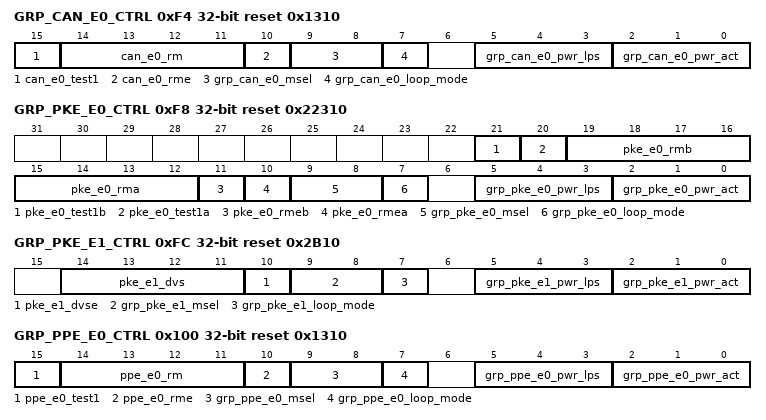
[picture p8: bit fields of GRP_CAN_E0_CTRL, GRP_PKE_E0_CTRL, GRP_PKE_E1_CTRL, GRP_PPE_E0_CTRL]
0xF4 GRP_CAN_E0_CTRL reset 0x1310
  [15] can_e0_test1 — TEST1
  [14:11] can_e0_rm — RM
  [10] can_e0_rme — RME
  [9:8] grp_can_e0_msel — *01 - This memory group can do normal mbist; *10 - This memory group can do DRF mbist; *11 - This memory group can do normal & DRF mbist
  [7] grp_can_e0_loop_mode — *0 - Assist loop mode; *1 - Don't assist loop mode
  [5:3] grp_can_e0_pwr_lps — Reserved for grp_@_pwr_lps for memory groups power controlled by SYSPMC. Setted before chip goes to SLEEP.Used to controll power mode of this memory group when chip is in SLEEP. For FTC_ULP mem, pwr_lps[2:0] map to {SLP,RET,NAP}; For SNPS mem, pwr_lps[2:0] map to {SD,DS,LS}. *000 - active *001 - light sleep *010 - deep sleep *100 - shut down
  [2:0] grp_can_e0_pwr_act — Used to controll power mode of this memory group when chip is ACTIVE. For FTC_ULP mem, pwr_act[2:0] map to {SLP,RET,NAP}; For SNPS mem, pwr_act[2:0] map to {SD,DS,LS}. *000 - active *001 - light sleep *010 - deep sleep *100 - shut down
0xF8 GRP_PKE_E0_CTRL reset 0x22310
  [21] pke_e0_test1b — TEST1B
  [20] pke_e0_test1a — TEST1A
  [19:16] pke_e0_rmb — RMB
  [15:12] pke_e0_rma — RMA
  [11] pke_e0_rmeb — RMEB
  [10] pke_e0_rmea — RMEA
  [9:8] grp_pke_e0_msel — *01 - This memory group can do normal mbist; *10 - This memory group can do DRF mbist; *11 - This memory group can do normal & DRF mbist
  [7] grp_pke_e0_loop_mode — *0 - Assist loop mode; *1 - Don't assist loop mode
  [5:3] grp_pke_e0_pwr_lps — Reserved for grp_@_pwr_lps for memory groups power controlled by SYSPMC. Setted before chip goes to SLEEP.Used to controll power mode of this memory group when chip is in SLEEP. For FTC_ULP mem, pwr_lps[2:0] map to {SLP,RET,NAP}; For SNPS mem, pwr_lps[2:0] map to {SD,DS,LS}. *000 - active *001 - light sleep *010 - deep sleep *100 - shut down
  [2:0] grp_pke_e0_pwr_act — Used to controll power mode of this memory group when chip is ACTIVE. For FTC_ULP mem, pwr_act[2:0] map to {SLP,RET,NAP}; For SNPS mem, pwr_act[2:0] map to {SD,DS,LS}. *000 - active *001 - light sleep *010 - deep sleep *100 - shut down
0xFC GRP_PKE_E1_CTRL reset 0x2B10
  [14:11] pke_e1_dvs — DVS
  [10] pke_e1_dvse — DVSE
  [9:8] grp_pke_e1_msel — *01 - This memory group can do normal mbist; *10 - This memory group can do DRF mbist; *11 - This memory group can do normal & DRF mbist
  [7] grp_pke_e1_loop_mode — *0 - Assist loop mode; *1 - Don't assist loop mode
  [5:3] grp_pke_e1_pwr_lps — Reserved for grp_@_pwr_lps for memory groups power controlled by SYSPMC. Setted before chip goes to SLEEP.Used to controll power mode of this memory group when chip is in SLEEP. For FTC_ULP mem, pwr_lps[2:0] map to {SLP,RET,NAP}; For SNPS mem, pwr_lps[2:0] map to {SD,DS,LS}. *000 - active *001 - light sleep *010 - deep sleep *100 - shut down
  [2:0] grp_pke_e1_pwr_act — Used to controll power mode of this memory group when chip is ACTIVE. For FTC_ULP mem, pwr_act[2:0] map to {SLP,RET,NAP}; For SNPS mem, pwr_act[2:0] map to {SD,DS,LS}. *000 - active *001 - light sleep *010 - deep sleep *100 - shut down
0x100 GRP_PPE_E0_CTRL reset 0x1310
  [15] ppe_e0_test1 — TEST1
  [14:11] ppe_e0_rm — RM
  [10] ppe_e0_rme — RME
  [9:8] grp_ppe_e0_msel — *01 - This memory group can do normal mbist; *10 - This memory group can do DRF mbist; *11 - This memory group can do normal & DRF mbist
  [7] grp_ppe_e0_loop_mode — *0 - Assist loop mode; *1 - Don't assist loop mode
  [5:3] grp_ppe_e0_pwr_lps — Reserved for grp_@_pwr_lps for memory groups power controlled by SYSPMC. Setted before chip goes to SLEEP.Used to controll power mode of this memory group when chip is in SLEEP. For FTC_ULP mem, pwr_lps[2:0] map to {SLP,RET,NAP}; For SNPS mem, pwr_lps[2:0] map to {SD,DS,LS}. *000 - active *001 - light sleep *010 - deep sleep *100 - shut down
  [2:0] grp_ppe_e0_pwr_act — Used to controll power mode of this memory group when chip is ACTIVE. For FTC_ULP mem, pwr_act[2:0] map to {SLP,RET,NAP}; For SNPS mem, pwr_act[2:0] map to {SD,DS,LS}. *000 - active *001 - light sleep *010 - deep sleep *100 - shut down
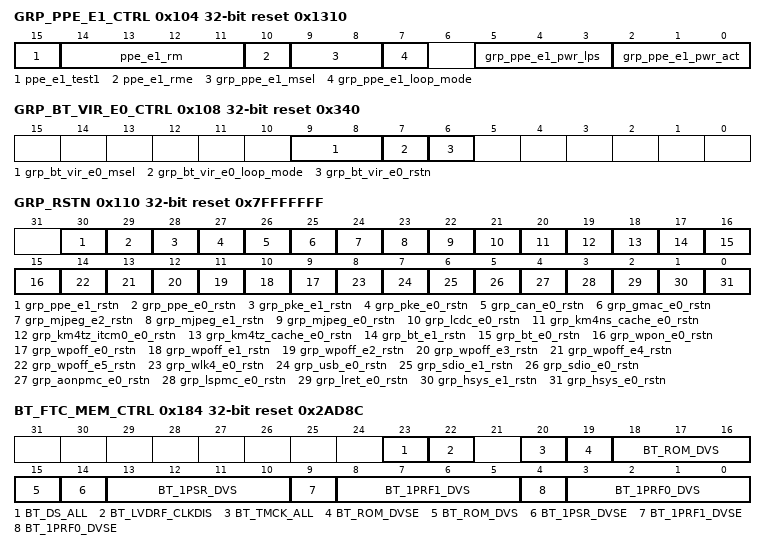
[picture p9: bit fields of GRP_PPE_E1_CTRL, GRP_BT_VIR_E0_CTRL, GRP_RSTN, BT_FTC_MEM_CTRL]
0x104 GRP_PPE_E1_CTRL reset 0x1310
  [15] ppe_e1_test1 — TEST1
  [14:11] ppe_e1_rm — RM
  [10] ppe_e1_rme — RME
  [9:8] grp_ppe_e1_msel — *01 - This memory group can do normal mbist; *10 - This memory group can do DRF mbist; *11 - This memory group can do normal & DRF mbist
  [7] grp_ppe_e1_loop_mode — *0 - Assist loop mode; *1 - Don't assist loop mode
  [5:3] grp_ppe_e1_pwr_lps — Reserved for grp_@_pwr_lps for memory groups power controlled by SYSPMC. Setted before chip goes to SLEEP.Used to controll power mode of this memory group when chip is in SLEEP. For FTC_ULP mem, pwr_lps[2:0] map to {SLP,RET,NAP}; For SNPS mem, pwr_lps[2:0] map to {SD,DS,LS}. *000 - active *001 - light sleep *010 - deep sleep *100 - shut down
  [2:0] grp_ppe_e1_pwr_act — Used to controll power mode of this memory group when chip is ACTIVE. For FTC_ULP mem, pwr_act[2:0] map to {SLP,RET,NAP}; For SNPS mem, pwr_act[2:0] map to {SD,DS,LS}. *000 - active *001 - light sleep *010 - deep sleep *100 - shut down
0x108 GRP_BT_VIR_E0_CTRL reset 0x340
  [9:8] grp_bt_vir_e0_msel — *01 - This memory group can do normal mbist; *10 - This memory group can do DRF mbist; *11 - This memory group can do normal & DRF mbist
  [7] grp_bt_vir_e0_loop_mode — *0 - Assist loop mode; *1 - Don't assist loop mode
  [6] grp_bt_vir_e0_rstn — *0 - Reset mbist circuit of this memory group; *1 - Release mbist circuit of this memory group.
0x110 GRP_RSTN reset 0x7FFFFFFF
  [30] grp_ppe_e1_rstn — *0 - Reset mbist circuit of this memory group; *1 - Release mbist circuit of this memory group.
  [29] grp_ppe_e0_rstn — *0 - Reset mbist circuit of this memory group; *1 - Release mbist circuit of this memory group.
  [28] grp_pke_e1_rstn — *0 - Reset mbist circuit of this memory group; *1 - Release mbist circuit of this memory group.
  [27] grp_pke_e0_rstn — *0 - Reset mbist circuit of this memory group; *1 - Release mbist circuit of this memory group.
  [26] grp_can_e0_rstn — *0 - Reset mbist circuit of this memory group; *1 - Release mbist circuit of this memory group.
  [25] grp_gmac_e0_rstn — *0 - Reset mbist circuit of this memory group; *1 - Release mbist circuit of this memory group.
  [24] grp_mjpeg_e2_rstn — *0 - Reset mbist circuit of this memory group; *1 - Release mbist circuit of this memory group.
  [23] grp_mjpeg_e1_rstn — *0 - Reset mbist circuit of this memory group; *1 - Release mbist circuit of this memory group.
  [22] grp_mjpeg_e0_rstn — *0 - Reset mbist circuit of this memory group; *1 - Release mbist circuit of this memory group.
  [21] grp_lcdc_e0_rstn — *0 - Reset mbist circuit of this memory group; *1 - Release mbist circuit of this memory group.
  [20] grp_km4ns_cache_e0_rstn — *0 - Reset mbist circuit of this memory group; *1 - Release mbist circuit of this memory group.
  [19] grp_km4tz_itcm0_e0_rstn — *0 - Reset mbist circuit of this memory group; *1 - Release mbist circuit of this memory group.
  [18] grp_km4tz_cache_e0_rstn — *0 - Reset mbist circuit of this memory group; *1 - Release mbist circuit of this memory group.
  [17] grp_bt_e1_rstn — *0 - Reset mbist circuit of this memory group; *1 - Release mbist circuit of this memory group.
  [16] grp_bt_e0_rstn — *0 - Reset mbist circuit of this memory group; *1 - Release mbist circuit of this memory group.
  [15] grp_wpon_e0_rstn — *0 - Reset mbist circuit of this memory group; *1 - Release mbist circuit of this memory group.
  [n+9] grp_wpoff_e{n}_rstn (n=0..5) — *0 - Reset mbist circuit of this memory group; *1 - Release mbist circuit of this memory group.
  [8] grp_wlk4_e0_rstn — *0 - Reset mbist circuit of this memory group; *1 - Release mbist circuit of this memory group.
  [7] grp_usb_e0_rstn — *0 - Reset mbist circuit of this memory group; *1 - Release mbist circuit of this memory group.
  [6] grp_sdio_e1_rstn — *0 - Reset mbist circuit of this memory group; *1 - Release mbist circuit of this memory group.
  [5] grp_sdio_e0_rstn — *0 - Reset mbist circuit of this memory group; *1 - Release mbist circuit of this memory group.
  [4] grp_aonpmc_e0_rstn — *0 - Reset mbist circuit of this memory group; *1 - Release mbist circuit of this memory group.
  [3] grp_lspmc_e0_rstn — *0 - Reset mbist circuit of this memory group; *1 - Release mbist circuit of this memory group.
  [2] grp_lret_e0_rstn — *0 - Reset mbist circuit of this memory group; *1 - Release mbist circuit of this memory group.
  [1] grp_hsys_e1_rstn — *0 - Reset mbist circuit of this memory group; *1 - Release mbist circuit of this memory group.
  [0] grp_hsys_e0_rstn — *0 - Reset mbist circuit of this memory group; *1 - Release mbist circuit of this memory group.
0x184 BT_FTC_MEM_CTRL reset 0x2AD8C
  [23] BT_DS_ALL — 1 - All BT memory switch to Deep Sleep mode 0 - Power mode of BT memory are controlled by BTPMC
  [22] BT_LVDRF_CLKDIS
  [20] BT_TMCK_ALL
  [19] BT_ROM_DVSE
  [18:15] BT_ROM_DVS — FSNOU_A_SPNN
  [14] BT_1PSR_DVSE — Not used in Lite
  [13:10] BT_1PSR_DVS — Not used in Lite
  [9] BT_1PRF1_DVSE
  [8:5] BT_1PRF1_DVS — FSNOU_A_SYNL
  [4] BT_1PRF0_DVSE
  [3:0] BT_1PRF0_DVS — FSNOU_A_SYNL
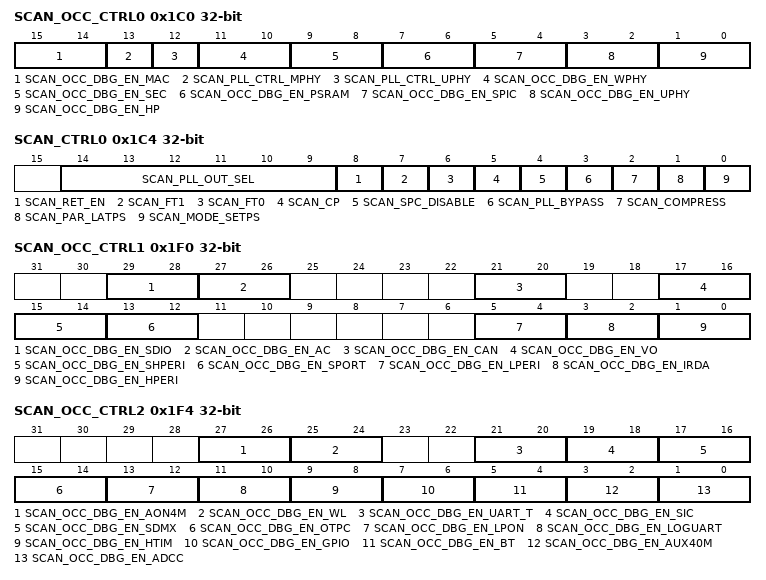
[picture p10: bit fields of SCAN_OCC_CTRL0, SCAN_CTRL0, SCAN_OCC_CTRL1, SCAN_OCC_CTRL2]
0x1C0 SCAN_OCC_CTRL0
  [15:14] SCAN_OCC_DBG_EN_MAC
  [13] SCAN_PLL_CTRL_MPHY — scan pll ctrl mipiphy
  [12] SCAN_PLL_CTRL_UPHY
  [11:10] SCAN_OCC_DBG_EN_WPHY
  [9:8] SCAN_OCC_DBG_EN_SEC
  [7:6] SCAN_OCC_DBG_EN_PSRAM
  [5:4] SCAN_OCC_DBG_EN_SPIC
  [3:2] SCAN_OCC_DBG_EN_UPHY
  [1:0] SCAN_OCC_DBG_EN_HP
0x1C4 SCAN_CTRL0
  [14:9] SCAN_PLL_OUT_SEL
  [8] SCAN_RET_EN — scan retention test enable
  [7] SCAN_FT1 — scan ft mode1
  [6] SCAN_FT0 — scan ft mode0
  [5] SCAN_CP — scan cp mode
  [4] SCAN_SPC_DISABLE
  [3] SCAN_PLL_BYPASS
  [2] SCAN_COMPRESS
  [1] SCAN_PAR_LATPS — Used as scan latch enable bit . If want to change scan par from func setting , set this bit to 1 first , then write func register will also effect scan shadow register .
  [0] SCAN_MODE_SETPS — scan mode enable . It is a level signal , write 1 will trigger into scan mode
0x1F0 SCAN_OCC_CTRL1
  [29:28] SCAN_OCC_DBG_EN_SDIO, [27:26] SCAN_OCC_DBG_EN_AC, [21:20] SCAN_OCC_DBG_EN_CAN, [17:16] SCAN_OCC_DBG_EN_VO, [15:14] SCAN_OCC_DBG_EN_SHPERI, [13:12] SCAN_OCC_DBG_EN_SPORT, [5:4] SCAN_OCC_DBG_EN_LPERI, [3:2] SCAN_OCC_DBG_EN_IRDA, [1:0] SCAN_OCC_DBG_EN_HPERI
0x1F4 SCAN_OCC_CTRL2
  [27:26] SCAN_OCC_DBG_EN_AON4M, [25:24] SCAN_OCC_DBG_EN_WL, [21:20] SCAN_OCC_DBG_EN_UART_T, [19:18] SCAN_OCC_DBG_EN_SIC, [17:16] SCAN_OCC_DBG_EN_SDMX, [15:14] SCAN_OCC_DBG_EN_OTPC, [13:12] SCAN_OCC_DBG_EN_LPON, [11:10] SCAN_OCC_DBG_EN_LOGUART, [9:8] SCAN_OCC_DBG_EN_HTIM, [7:6] SCAN_OCC_DBG_EN_GPIO, [5:4] SCAN_OCC_DBG_EN_BT, [3:2] SCAN_OCC_DBG_EN_AUX40M, [1:0] SCAN_OCC_DBG_EN_ADCC
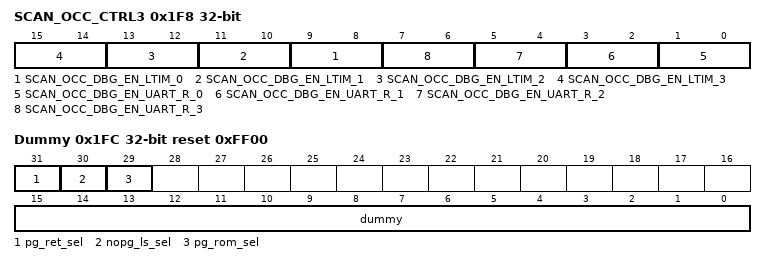
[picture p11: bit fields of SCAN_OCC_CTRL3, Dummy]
0x1F8 SCAN_OCC_CTRL3
  [2n+9:2n+8] SCAN_OCC_DBG_EN_LTIM_{n} (n=0..3), [2n+1:2n] SCAN_OCC_DBG_EN_UART_R_{n} (n=0..3)
0x1FC Dummy reset 0xFF00
  [31] pg_ret_sel — change all pg ram group power mode to ret
  [30] nopg_ls_sel — change all nopg ram group power mode to ls
  [29] pg_rom_sel — change all rom group power mode to slp
  [15:0] dummy
